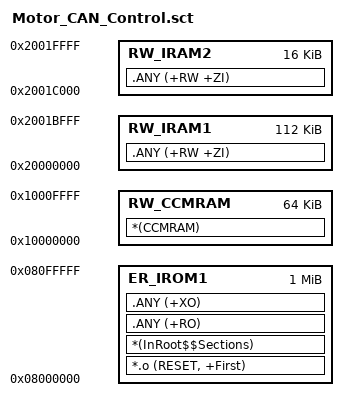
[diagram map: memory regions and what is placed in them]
; STM32F407 scatter file with a dedicated 64 KiB CCM RAM region.
; CCM RAM is CPU-only: do not place Ethernet/CAN DMA descriptors or buffers here.

LR_IROM1 0x08000000 0x00100000  {
  ER_IROM1 0x08000000 0x00100000  {
    *.o (RESET, +First)
    *(InRoot$$Sections)
    .ANY (+RO)
    .ANY (+XO)
  }

  RW_CCMRAM 0x10000000 0x00010000  {
    *(CCMRAM)
  }

  RW_IRAM1 0x20000000 0x0001C000  {
    .ANY (+RW +ZI)
  }

  RW_IRAM2 0x2001C000 0x00004000  {
    .ANY (+RW +ZI)
  }
}
